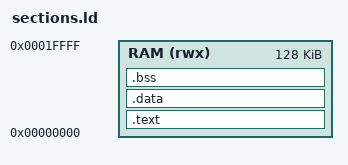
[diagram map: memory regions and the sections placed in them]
MEMORY
{
    RAM (rwx) : ORIGIN = 0x00000000, LENGTH = 0x20000
}

SECTIONS
{
    .text : {
        . = ALIGN(4);
        *(.text)
        *(.text*)
        *(.rodata)
        *(.rodata*)
        *(.srodata)
        *(.srodata*)
        . = ALIGN(4);
        _etext = .;
    } > RAM

    .data : {
        . = ALIGN(4);
        _sdata = .;
        *(.data)
        *(.data*)
        *(.sdata)
        *(.sdata*)
        . = ALIGN(4);
        _edata = .;
    } > RAM

    .bss : {
        . = ALIGN(4);
        _sbss = .;
        *(.bss)
        *(.bss*)
        *(.sbss)
        *(.sbss*)
        *(COMMON)
        . = ALIGN(4);
        _ebss = .;
    } > RAM
}
